# M5531 register map
File version: 1.0
Registers are 32-bit, read-write, reset 0x0 unless marked. A register's access mark holds for its fields unless they carry their own. Offsets are from the block's base; [hi:lo] are bit positions; {n}, {i} and the like mark numbered series; 'fields as' and 'values as' point back to an identical list.

## CRYPTO_NS (part 2 of 2) — CRYPTO Register Map
Base 0x5020A000
{0x358+4i} CRYPTO_HMAC_FDBCK{i} (i=0..87) — SHA/HMAC Output Feedback Data {i} After SHA/HMAC Operation
  [31:0] FDBCK — SHA/HMAC Feedback Information. The feedback value is 1728 bits in size for SHA1/2 and 2784 bits in size for SHA3. The SHA/HMAC engine uses the data from CRYPTO_HMAC_FDBCKx as the data inputted to CRYPTO_HMAC_FDBCKx for the next block in DMA cascade mode. The SHA/HMAC engine outputs feedback information for initial setting in the next block's operation. Software can store that feedback value temporarily. After switching back, fill the stored feedback value to CRYPTO_HMAC_FDBCKx in the same operation, and then continue the operation with the original setting.
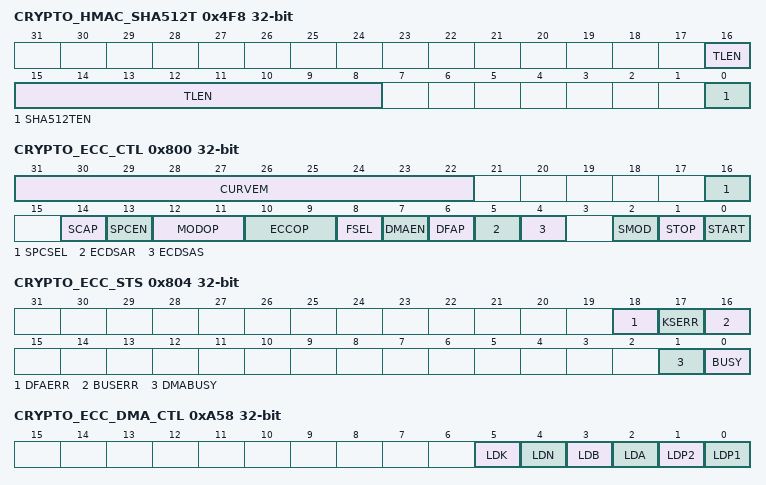
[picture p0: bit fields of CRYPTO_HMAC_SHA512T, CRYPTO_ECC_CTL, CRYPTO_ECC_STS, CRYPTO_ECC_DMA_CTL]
0x4F8 CRYPTO_HMAC_SHA512T — SHA/HMAC SHA512/t Control Register
  [16:8] TLEN — SHA512/t Output Digest Length. The TLEN is equal to value t of SHA512/t. It also means the output digest length of SHA512 /t. Note: TLEN 512, and TLEN is not 384
  [0] SHA512TEN — SHA512/t Engine Enable Bit
    0=Execute other function; 1=Execute SHA512/t function if SHA3EN=0, and SM3EN=0
0x4FC CRYPTO_HMAC_FBADDR — SHA/HMAC DMA Feedback Address Register
  [31:0] FBADDR — SHA/HMAC DMA Feedback Address. In DMA cascade mode, software can update DMA feedback address register for automatically reading and writing feedback values via DMA. The FBADDR keeps the feedback address of the feedback data for the next cascade operation. Based on the feedback address, the SHA/HMAC accelerator can read the feedback data of the last cascade operation from SRAM memory space and write the feedback data of the current cascade operation to SRAM memory space. The start of feedback address should be located at word boundary. In other words, bit 1 and 0 of FBADDR are ignored. FBADDR can be read and written. In DMA mode, software can update the next CRYPTO_HMAC_FBADDR before triggering START.
{0x500+4i} CRYPTO_HMAC_SHAKEDGST{i} ro (i=0..41) — SHA/HMAC SHAKE Digest Message {i}
  [31:0] DGST — SHA/HMAC SHAKE Digest Message Register. For SHAKE-128, the digest is stored in CRYPTO_HMAC_SHAKEDGST0 0 ~ CRYPTO_HMAC_ SHAKEDGST0 41. For SHAKE-256, the digest is stored in CRYPTO_HMAC_SHAKEDGST0 0 ~ CRYPTO_HMAC_ SHAKEDGST0 33.
0x800 CRYPTO_ECC_CTL — ECC Control Register
  [31:22] CURVEM — The key length of elliptic curve.
  [16] SPCSEL — Special Curve Selection
    0=Montgomery curve when SPCEN is 1; 1=Edwards curve when SPCEN is 1. SM2 curve when SPCEN is 0
  [14] SCAP — Side-channel Attack Protection
    0=Full speed without side-channel protection; 1=Less speed with side-channel protection
  [13] SPCEN — Special Curve Enable
    0=NIST suggested or SM2 curve; 1=Montgomery curve or Edwards curve
  [12:11] MODOP — Modulus Operation for PF. When SMOD is 0,
    0=Division:. Modulo:; 1=Multiplication:. Exponential:; 2=Addition:. Square root:; 3=Subtraction:
  [10:9] ECCOP — Point Operation for BF and PF. Besides above three input data, point operations still need the parameters of elliptic curve (CURVEA, CURVEB, CURVEN and CURVEM) as shown in Figure 6.27-11.
    0=Point multiplication:; 1=Modulus operation: choose by MODOP (CRYPTO_ECC_CTL[12:11]); 2=Point addition:; 3=Point doubling:
  [8] FSEL — Field Selection
    0=Binary Field (GF(2m )); 1=Prime Field (GF(p))
  [7] DMAEN — ECC Accelerator DMA Enable Bit. Only when START and DMAEN are 1, ECC DMA engine will be active.
    0=ECC DMA engine Disabled; 1=ECC DMA engine Enabled
  [6] DFAP — Differential Fault Attack Protection
    0=ECC engine differential fault attack protection Disabled; 1=ECC engine differential fault attack protection Enabled
  [5] ECDSAR — Generate R in ECDSA Signature Generation
    0=No effect; 1=Formula for generating R
  [4] ECDSAS — Generate S in ECDSA Signature Generation
    0=No effect; 1=Formula for generating S
  [2] SMOD — Special Modulus Operation in Prime Field
    0=Normal modulus operation; 1=Special modulus operation
  [1] STOP — ECC Accelerator Stop. This bit is always 0 when it is read back. Remember to clear ECC interrupt flag after stopping ECC accelerator.
    0=No effect; 1=Abort ECC accelerator and make it into idle state
  [0] START — ECC Accelerator Start. This bit is always 0 when it is read back. ECC accelerator will ignore this START signal when BUSY flag is 1.
    0=No effect; 1=Start ECC accelerator. BUSY flag will be set
0x804 CRYPTO_ECC_STS ro — ECC Status Register
  [18] DFAERR — ECC Engine Differential Fault Attack Error Flag
    0=No error; 1=Differential Fault Attack happened in ECC engine. The results from ECC engine are incorrect
  [17] KSERR — ECC Engine Access Key Store Error Flag
    0=No error; 1=Access error will stop ECC engine
  [16] BUSERR — ECC DMA Access Bus Error Flag
    0=No error; 1=Bus error will stop DMA operation and ECC accelerator
  [1] DMABUSY — ECC DMA Busy Flag
    0=ECC DMA is idle or finished; 1=ECC DMA is busy
  [0] BUSY — ECC Accelerator Busy Flag. Note: Remember to clear ECC interrupt flag after ECC accelerator is finished
    0=The ECC accelerator is idle or finished; 1=The ECC accelerator is under processing and protects all registers
{0x808+4i} CRYPTO_ECC_X1_{i:02} (i=0..17) — ECC the X-coordinate Word{i} of the First Point
  [31:0] POINTX1 — ECC the X-coordinate Value of the First Point. For B-163 or K-163, POINTX1 is stored in CRYPTO_ECC_X1_00~CRYPTO_ECC_X1_05. For B-233 or K-233, POINTX1 is stored in CRYPTO_ECC_X1_00~CRYPTO_ECC_X1_07. For B-283 or K-283, POINTX1 is stored in CRYPTO_ECC_X1_00~CRYPTO_ECC_X1_08. For B-409 or K-409, POINTX1 is stored in CRYPTO_ECC_X1_00~CRYPTO_ECC_X1_12. For B-571 or K-571, POINTX1 is stored in CRYPTO_ECC_X1_00~CRYPTO_ECC_X1_17. For P-192, POINTX1 is stored in CRYPTO_ECC_X1_00~CRYPTO_ECC_X1_05. For P-224, POINTX1 is stored in CRYPTO_ECC_X1_00~CRYPTO_ECC_X1_06. For P-256 or SM2, POINTX1 is stored in CRYPTO_ECC_X1_00~CRYPTO_ECC_X1_07. For P-384, POINTX1 is stored in CRYPTO_ECC_X1_00~CRYPTO_ECC_X1_11. For P-521, POINTX1 is stored in CRYPTO_ECC_X1_00~CRYPTO_ECC_X1_16
{0x850+4i} CRYPTO_ECC_Y1_{i:02} (i=0..17) — ECC the Y-coordinate Word{i} of the First Point
  [31:0] POINTY1 — ECC the Y-coordinate Value of the First Point. For B-163 or K-163, POINTY1 is stored in CRYPTO_ECC_Y1_00~CRYPTO_ECC_Y1_05. For B-233 or K-233, POINTY1 is stored in CRYPTO_ECC_Y1_00~CRYPTO_ECC_Y1_07. For B-283 or K-283, POINTY1 is stored in CRYPTO_ECC_Y1_00~CRYPTO_ECC_Y1_08. For B-409 or K-409, POINTY1 is stored in CRYPTO_ECC_Y1_00~CRYPTO_ECC_Y1_12. For B-571 or K-571, POINTY1 is stored in CRYPTO_ECC_Y1_00~CRYPTO_ECC_Y1_17. For P-192, POINTY1 is stored in CRYPTO_ECC_Y1_00~CRYPTO_ECC_Y1_05. For P-224, POINTY1 is stored in CRYPTO_ECC_Y1_00~CRYPTO_ECC_Y1_06. For P-256 or SM2, POINTY1 is stored in CRYPTO_ECC_Y1_00~CRYPTO_ECC_Y1_07. For P-384, POINTY1 is stored in CRYPTO_ECC_Y1_00~CRYPTO_ECC_Y1_11. For P-521, POINTY1 is stored in CRYPTO_ECC_Y1_00~CRYPTO_ECC_Y1_16
{0x898+4i} CRYPTO_ECC_X2_{i:02} (i=0..17) — ECC the X-coordinate Word{i} of the Second Point
  [31:0] POINTX2 — ECC the X-coordinate Value of the Second Point. For B-163 or K-163, POINTX2 is stored in CRYPTO_ECC_X2_00~CRYPTO_ECC_X2_05. For B-233 or K-233, POINTX2 is stored in CRYPTO_ECC_X2_00~CRYPTO_ECC_X2_07. For B-283 or K-283, POINTX2 is stored in CRYPTO_ECC_X2_00~CRYPTO_ECC_X2_08. For B-409 or K-409, POINTX2 is stored in CRYPTO_ECC_X2_00~CRYPTO_ECC_X2_12. For B-571 or K-571, POINTX2 is stored in CRYPTO_ECC_X2_00~CRYPTO_ECC_X2_17. For P-192, POINTX2 is stored in CRYPTO_ECC_X2_00~CRYPTO_ECC_X2_05. For P-224, POINTX2 is stored in CRYPTO_ECC_X2_00~CRYPTO_ECC_X2_06. For P-256 or SM2, POINTX2 is stored in CRYPTO_ECC_X2_00~CRYPTO_ECC_X2_07. For P-384, POINTX2 is stored in CRYPTO_ECC_X2_00~CRYPTO_ECC_X2_11. For P-521, POINTX2 is stored in CRYPTO_ECC_X2_00~CRYPTO_ECC_X2_16
{0x8E0+4i} CRYPTO_ECC_Y2_{i:02} (i=0..17) — ECC the Y-coordinate Word{i} of the Second Point
  [31:0] POINTY2 — ECC the Y-coordinate Value of the Second Point. For B-163 or K-163, POINTY2 is stored in CRYPTO_ECC_Y2_00~CRYPTO_ECC_Y2_05. For B-233 or K-233, POINTY2 is stored in CRYPTO_ECC_Y2_00~CRYPTO_ECC_Y2_07. For B-283 or K-283, POINTY2 is stored in CRYPTO_ECC_Y2_00~CRYPTO_ECC_Y2_08. For B-409 or K-409, POINTY2 is stored in CRYPTO_ECC_Y2_00~CRYPTO_ECC_Y2_12. For B-571 or K-571, POINTY2 is stored in CRYPTO_ECC_Y2_00~CRYPTO_ECC_Y2_17. For P-192, POINTY2 is stored in CRYPTO_ECC_Y2_00~CRYPTO_ECC_Y2_05. For P-224, POINTY2 is stored in CRYPTO_ECC_Y2_00~CRYPTO_ECC_Y2_06. For P-256 or SM2, POINTY2 is stored in CRYPTO_ECC_Y2_00~CRYPTO_ECC_Y2_07. For P-384, POINTY2 is stored in CRYPTO_ECC_Y2_00~CRYPTO_ECC_Y2_11. For P-521, POINTY2 is stored in CRYPTO_ECC_Y2_00~CRYPTO_ECC_Y2_16
{0x928+4i} CRYPTO_ECC_A_{i:02} (i=0..17) — ECC the Parameter CURVEA Word{i} of Elliptic Curve
  [31:0] CURVEA — ECC the Parameter CURVEA Value of Elliptic Curve. For B-163 or K-163, CURVEA is stored in CRYPTO_ECC_A_00~CRYPTO_ECC_A_05. For B-233 or K-233, CURVEA is stored in CRYPTO_ECC_A_00~CRYPTO_ECC_A_07. For B-283 or K-283, CURVEA is stored in CRYPTO_ECC_A_00~CRYPTO_ECC_A_08. For B-409 or K-409, CURVEA is stored in CRYPTO_ECC_A_00~CRYPTO_ECC_A_12. For B-571 or K-571, CURVEA is stored in CRYPTO_ECC_A_00~CRYPTO_ECC_A_17. For P-192, CURVEA is stored in CRYPTO_ECC_A_00~CRYPTO_ECC_A_05. For P-224, CURVEA is stored in CRYPTO_ECC_A_00~CRYPTO_ECC_A_06. For P-256 or SM2, CURVEA is stored in CRYPTO_ECC_A_00~CRYPTO_ECC_A_07. For P-384, CURVEA is stored in CRYPTO_ECC_A_00~CRYPTO_ECC_A_11. For P-521, CURVEA is stored in CRYPTO_ECC_A_00~CRYPTO_ECC_A_16
{0x970+4i} CRYPTO_ECC_B_{i:02} (i=0..17) — ECC the Parameter CURVEB Word{i} of Elliptic Curve
  [31:0] CURVEB — ECC the Parameter CURVEB Value of Elliptic Curve. For B-163 or K-163, CURVEB is stored in CRYPTO_ECC_B_00~CRYPTO_ECC_B_05. For B-233 or K-233, CURVEB is stored in CRYPTO_ECC_B_00~CRYPTO_ECC_B_07. For B-283 or K-283, CURVEB is stored in CRYPTO_ECC_B_00~CRYPTO_ECC_B_08. For B-409 or K-409, CURVEB is stored in CRYPTO_ECC_B_00~CRYPTO_ECC_B_12. For B-521 or K-521, CURVEB is stored in CRYPTO_ECC_B_00~CRYPTO_ECC_B_17. For P-192, CURVEB is stored in CRYPTO_ECC_B_00~CRYPTO_ECC_B_05. For P-224, CURVEB is stored in CRYPTO_ECC_B_00~CRYPTO_ECC_B_06. For P-256 or SM2, CURVEB is stored in CRYPTO_ECC_B_00~CRYPTO_ECC_B_07. For P-384, CURVEB is stored in CRYPTO_ECC_B_00~CRYPTO_ECC_B_11. For P-521, CURVEB is stored in CRYPTO_ECC_B_00~CRYPTO_ECC_B_16
{0x9B8+4i} CRYPTO_ECC_N_{i:02} (i=0..17) — ECC the Parameter CURVEN Word{i} of Elliptic Curve
  [31:0] CURVEN — ECC the Parameter CURVEN Value of Elliptic Curve. In GF(p), CURVEN is the prime p. In GF(2m), CURVEN is the irreducible polynomial. For B-163 or K-163, CURVEN is stored in CRYPTO_ECC_N_00~CRYPTO_ECC_N_05. For B-233 or K-233, CURVEN is stored in CRYPTO_ECC_N_00~CRYPTO_ECC_N_07. For B-283 or K-283, CURVEN is stored in CRYPTO_ECC_N_00~CRYPTO_ECC_N_08. For B-409 or K-409, CURVEN is stored in CRYPTO_ECC_N_00~CRYPTO_ECC_N_12. For B-571 or K-571, CURVEN is stored in CRYPTO_ECC_N_00~CRYPTO_ECC_N_17. For P-192, CURVEN is stored in CRYPTO_ECC_N_00~CRYPTO_ECC_N_05. For P-224, CURVEN is stored in CRYPTO_ECC_N_00~CRYPTO_ECC_N_06. For P-256 or SM2, CURVEN is stored in CRYPTO_ECC_N_00~CRYPTO_ECC_N_07. For P-384, CURVEN is stored in CRYPTO_ECC_N_00~CRYPTO_ECC_N_11. For P-521, CURVEN is stored in CRYPTO_ECC_N_00~CRYPTO_ECC_N_16
{0xA00+4i} CRYPTO_ECC_K_{i:02} wo (i=0..17) — ECC the Scalar SCALARK Word{i} of Point Multiplication
  [31:0] SCALARK — ECC the Scalar SCALARK Value of Point Multiplication. Because the SCALARK usually stores the private key, ECC accelerator do not allow to read the register SCALARK. For B-163 or K-163, SCALARK is stored in CRYPTO_ECC_K_00~CRYPTO_ECC_K_05. For B-233 or K-233, SCALARK is stored in CRYPTO_ECC_K_00~CRYPTO_ECC_K_07. For B-283 or K-283, SCALARK is stored in CRYPTO_ECC_K_00~CRYPTO_ECC_K_08. For B-409 or K-409, SCALARK is stored in CRYPTO_ECC_K_00~CRYPTO_ECC_K_12. For B-571 or K-571, SCALARK is stored in CRYPTO_ECC_K_00~CRYPTO_ECC_K_17. For P-192, SCALARK is stored in CRYPTO_ECC_K_00~CRYPTO_ECC_K_05. For P-224, SCALARK is stored in CRYPTO_ECC_K_00~CRYPTO_ECC_K_06. For P-256 or SM2, SCALARK is stored in CRYPTO_ECC_K_00~CRYPTO_ECC_K_07. For P-384, SCALARK is stored in CRYPTO_ECC_K_00~CRYPTO_ECC_K_11. For P-521, SCALARK is stored in CRYPTO_ECC_K_00~CRYPTO_ECC_K_16
0xA48 CRYPTO_ECC_SADDR — ECC DMA Source Address Register
0xA4C CRYPTO_ECC_DADDR — ECC DMA Destination Address Register
  [31:0] DADDR — ECC DMA Destination Address. The ECC accelerator supports DMA function to transfer the DATA and PARAMETER between SRAM memory and ECC accelerator. The DADDR keeps the destination address of the data buffer where output data of ECC engine will be stored. Based on the destination address, the ECC accelerator can write the result data back to SRAM memory space after the ECC operation is finished. The start of destination address should be located at word boundary. That is, bit 1 and 0 of DADDR are ignored. DADDR can be read and written. In DMA mode, software must update the CRYPTO_ECC_DADDR before triggering START.
0xA50 CRYPTO_ECC_STARTREG — ECC Starting Address of Updated Registers
  [31:0] STARTREG — ECC Starting Address of Updated Registers. The address of the updated registers that DMA feeds the first data or parameter to ECC engine. When ECC engine is active, ECC accelerator does not allow users to modify STARTRE.G. For example, to update input data from register CRYPTO_ECC POINTX1. Thus, the value of STARTREG is 0x808.
0xA54 CRYPTO_ECC_WORDCNT — ECC DMA Word Count
  [31:0] WORDCNT — ECC DMA Word Count. The CRYPTO_ECC_WORDCNT keeps the word count of source data that is for the required input data of ECC accelerator with various operations in DMA mode. Although CRYPTO_ECC_WORDCNT is 32-bit, the maximum of word count in ECC accelerator is 144 words. CRYPTO_ECC_WORDCNT can be read and written.
0xA58 CRYPTO_ECC_DMA_CTL — ECC DMA Control Register
  [5] LDK — The Control Signal of Register for SCALARK
    0=The register for SCALARK is not modified by DMA or user; 1=The register for SCALARK is modified by DMA or user
  [4] LDN — The Control Signal of Register for the Parameter CURVEN of Elliptic Curve
    0=The register for CURVEN is not modified by DMA or user; 1=The register for CURVEN is modified by DMA or user
  [3] LDB — The Control Signal of Register for the Parameter CURVEB of Elliptic Curve
    0=The register for CURVEB is not modified by DMA or user; 1=The register for CURVEB is modified by DMA or user
  [2] LDA — The Control Signal of Register for the Parameter CURVEA of Elliptic Curve
    0=The register for CURVEA is not modified by DMA or user; 1=The register for CURVEA is modified by DMA or user
  [1] LDP2 — The Control Signal of Register POINTX2 and POINTY2 for the x and Y Coordinate of the Second Point
    0=The register for POINTX2 and POINTY2 is not modified by DMA or user; 1=The register for POINTX2 and POINTY2 is modified by DMA or user
  [0] LDP1 — The Control Signal of Register POINTX1 and POINTY1 for the x and Y Coordinate of the First Point
    0=The register for POINTX1 and POINTY1 is not modified by DMA or user; 1=The register for POINTX1 and POINTY1 is modified by DMA or user
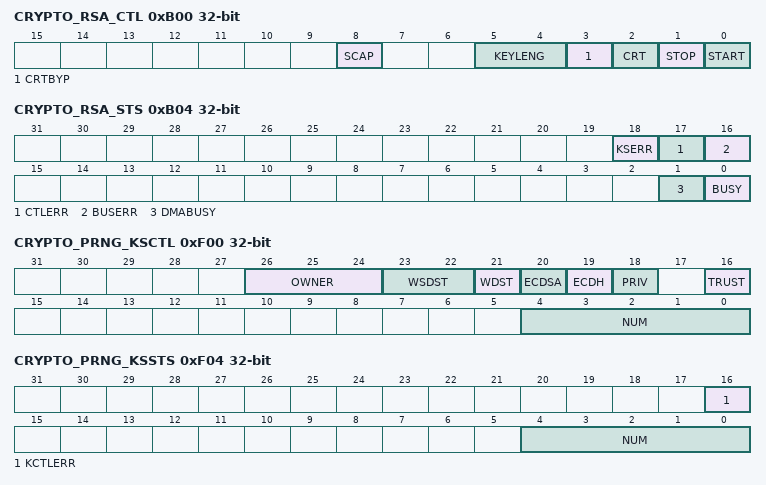
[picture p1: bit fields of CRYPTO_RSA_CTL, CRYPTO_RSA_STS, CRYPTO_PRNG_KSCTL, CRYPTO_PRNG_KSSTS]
0xB00 CRYPTO_RSA_CTL — RSA Control Register
  [8] SCAP — Side Channel Attack Protection Enable Control
    0=Side Channel Attack Protection Disabled; 1=Side Channel Attack Protection Enabled
  [5:4] KEYLENG — The Key Length of RSA Operation
    0=1024-bits; 1=2048-bits; 2=3072-bits; 3=4096-bits
  [3] CRTBYP — CRT Bypass Enable Control. CRT bypass is only used in CRT decryption with the same key. CRT mode saved the data when the first time CRT decryption (CRTBYP is 0), then users can use these already known data to bypass some operation when the second time to the latest time CRT decryption (CRTBYP is 1) for improve performance. Note: Users cannot set CRTBYP to 1 in non-CRT mode (CRT (CRYPTO_RSA_CTL[2]) is 0).
    0=CRT Bypass Disabled; 1=CRT Bypass Enabled
  [2] CRT — CRT Enable Control. CRT is only used in decryption with key length 2048, 3072,4096 bits.
    0=CRT Disabled; 1=CRT Enabled
  [1] STOP — RSA Accelerator Stop. This bit is always 0 when it is read back. Remember to clear RSA interrupt flag after stopping RSA accelerator.
    0=No effect; 1=Abort RSA accelerator and make it into initial state
  [0] START — RSA Accelerator Start. This bit is always 0 when it is read back. RSA accelerator will ignore this START signal when BUSY flag is 1.
    0=No effect; 1=Start RSA accelerator. BUSY flag will be set
0xB04 CRYPTO_RSA_STS ro — RSA Status Register
  [18] KSERR — RSA Engine Access Key Store Error Flag
    0=No error; 1=Access error will stop RSA engine
  [17] CTLERR — RSA Control Register Error Flag. Note: If users use the error combination of control, even though they don't set START(CRYPTO_RSA_CTL[0]) to 1, CTLERR still be set to 1.
    0=No error; 1=RSA control error. RSA will not start in the unsupported situation
  [16] BUSERR — RSA DMA Access Bus Error Flag
    0=No error; 1=Bus error will stop DMA operation and RSA accelerator
  [1] DMABUSY — RSA DMA Busy Flag
    0=RSA DMA is idle or finished; 1=RSA DMA is busy
  [0] BUSY — RSA Accelerator Busy Flag. Remember to clear RSA interrupt flag after RSA accelerator finished.
    0=The RSA accelerator is idle or finished; 1=The RSA accelerator is under processing and protects all registers
0xB08 CRYPTO_RSA_SADDR0 — RSA DMA Source Address Register0
  [31:0] SADDR0 — RSA DMA Source Address Register0. The RSA accelerator supports DMA function to transfer the DATA and PARAMETER between SRAM memory space and RSA accelerator. This register is stored the address of RSA the Base of Exponentiation (M).
0xB0C CRYPTO_RSA_SADDR1 — RSA DMA Source Address Register1
  [31:0] SADDR1 — RSA DMA Source Address Register1. The RSA accelerator supports DMA function to transfer the DATA and PARAMETER between SRAM memory space and RSA accelerator. This register is stored the address of RSA the Base of Modulus Operation (N).
0xB10 CRYPTO_RSA_SADDR2 — RSA DMA Source Address Register2
  [31:0] SADDR2 — RSA DMA Source Address Register2. The RSA accelerator supports DMA function to transfer the DATA and PARAMETER between SRAM memory space and RSA accelerator. This register is stored the address of RSA the Exponent of Exponentiation (E).
0xB14 CRYPTO_RSA_SADDR3 — RSA DMA Source Address Register3
  [31:0] SADDR3 — RSA DMA Source Address Register3. The RSA accelerator supports DMA function to transfer the DATA and PARAMETER between SRAM memory space and RSA accelerator. This register is stored the address of RSA the Factor of Modulus Operation (p).
0xB18 CRYPTO_RSA_SADDR4 — RSA DMA Source Address Register4
  [31:0] SADDR4 — RSA DMA Source Address Register4. The RSA accelerator supports DMA function to transfer the DATA and PARAMETER between SRAM memory space and RSA accelerator. This register is stored the address of RSA the Factor of Modulus Operation (q).
0xB1C CRYPTO_RSA_DADDR — RSA DMA Destination Address Register
  [31:0] DADDR — RSA DMA Destination Address Register. The RSA accelerator supports DMA function to transfer the DATA and PARAMETER between SRAM memory space and RSA accelerator. This register is stored the address of RSA DMA Destination Address Register (Ans).
{0xB20+4i} CRYPTO_RSA_MADDR{i} (i=0..6) — RSA DMA Middle Address Register{i}
  [31:0] MADDR{i} — RSA DMA Middle Address Register{i}. The RSA accelerator supports DMA function to transfer the DATA and PARAMETER between SRAM memory space and RSA accelerator.
0xF00 CRYPTO_PRNG_KSCTL wo — PRNG Key Control Register
  [26:24] OWNER — Write Key Owner Selection Bits
    0=Only for AES use; 1=Only for HMAC engine (excludes HMAC-SHA3 series) use; 4=Only for ECC engine use; 5=Only for CPU engine use
  [23:22] WSDST — Write Key Store Destination
    0=Key is written to the SRAM of Key Store; 1=Key is written to the FLASH of Key Store; 2=Key is written to the OTP of Key Store
  [21] WDST — Write Key Destination
    0=Key is written to registers CRYPTO_PRNG_KEYx; 1=Key is written to Key Store
  [20] ECDSA — ECDSA Control Bit. Note: When ECDSA was set to '1', 1. PRNG seed must be from TRNG and key must be written to the SRAM of Key Store (WSDST, CRYPTO_PRNG_KSCTL[23:22] must set to '00'). Otherwise, KCTLERR will become '1'(CRYPTO_PRNG_KSSTS[16]). 2. Key must in the interval [1, n-1] (the parameter n is from ECC). The value of n cannot be 0 or 1, otherwise, PRNG will always keep busy.
    1=Key is written to Key Store and used in ECDSA
  [19] ECDH — ECDH Control Bit. Note: When ECDH was set to '1', 1. PRNG seed must be from TRNG and key must be written to the SRAM of Key Store (WSDST, CRYPTO_PRNG_KSCTL[23:22] must set to '00'). Otherwise, KCTLERR will become '1'(CRYPTO_PRNG_KSSTS[16]).2. Key must in the interval [1, n-1] (the parameter n is from ECC). The value of n cannot be 0 or 1, otherwise, PRNG will always keep busy.
    1=key is written to Key Store and used in ECDH
  [18] PRIV — Write Key Privilege Selection Bit
    0=Set written key as the non-privilege key; 1=Set written key as the privilege key
  [16] TRUST — Write Key Trust Selection Bit
    0=Set written key as the non-secure key; 1=Set written key as the secure key
  [4:0] NUM — Write Key Number. The key number is sent to Key Store. Note: Only for destination Is OTP of Key Store.
0xF04 CRYPTO_PRNG_KSSTS ro — PRNG Key Status Register
  [16] KCTLERR — PRNG Key Control Register Error Flag
    0=No error; 1=PRNG key control error. When PRNG execute ECDSA or ECDH, but PRNG seed not from TRNG or key is not written to the SRAM of Key Store (WSDST, CRYPTO_PRNG_KSCTL[23:22] is not equal to '00')
  [4:0] NUM — Key Number. The key number is generated by Key Store
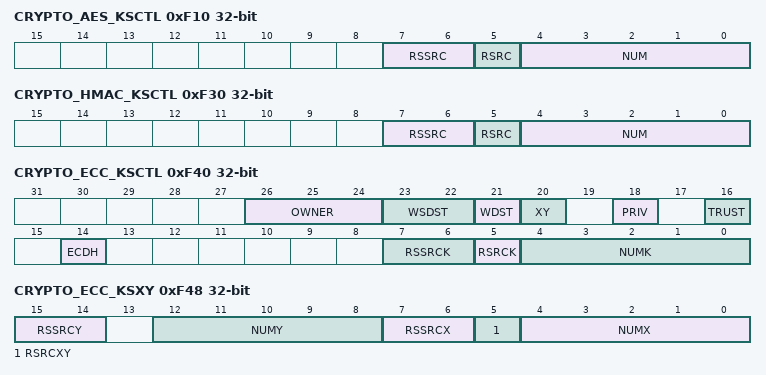
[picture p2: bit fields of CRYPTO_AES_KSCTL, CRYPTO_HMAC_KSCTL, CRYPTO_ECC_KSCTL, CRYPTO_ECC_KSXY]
0xF10 CRYPTO_AES_KSCTL wo — AES Key Control Register
  [7:6] RSSRC — Read Key Store Source. RSSRC takes effect only when RSRC is 1 (the key is from Key Store).
    0=Key is read from the SRAM of Key Store; 1=Key is read from the FLASH of Key Store; 2=Key is read from the OTP of Key Store
  [5] RSRC — Read Key Source
    0=Key is read from registers CRYPTO_AESx_KEYx; 1=Key is read from Key Store
  [4:0] NUM — Read Key Number. The key number is sent to Key Store
0xF30 CRYPTO_HMAC_KSCTL wo — HMAC Key Control Register
  [7:6] RSSRC — Read Key Store Source. RSSRC takes effect only when RSRC is 1 (the key is from Key Store).
    0=Key is read from the SRAM of Key Store; 1=Key is read from the FLASH of Key Store
  [5] RSRC — Read Key Source
    0=Key is read from HMAC registers; 1=Key is read from Key Store
  [4:0] NUM — Read Key Number. The key number is sent to Key Store
0xF40 CRYPTO_ECC_KSCTL wo — ECC Key Control Register
  [26:24] OWNER — Write Key Owner Selection Bits
    0=The ECDH written key is only for AES used; 1=The ECDH written key is only for HMAC engine used; 4=The ECDH written key is only for ECC engine used; 5=The ECDH written key is only for CPU engine use
  [23:22] WSDST — Write Key Store Destination. WSDST takes effect only when WDST is 1 (the key is written to Key Store).
    0=The ECDH written key is written to the SRAM of Key Store; 1=The ECDH written key is written to the FLASH of Key Store; 2=The ECDH written key is written to the OTP of Key Store
  [21] WDST — Write Key Destination
    0=The ECDH written key is in registers CRYPTO_ECC_X1 and CRYPTO_ECC_Y; 1=The ECDH written key is written to Key Store
  [20] XY — ECDH Output Select Bit
    0=The ECDH written key is from X-coordinate Value; 1=The ECDH written key is from Y-coordinate Value
  [18] PRIV — Write Key Privilege Selection Bit
    0=Set ECDH written key as the non-privilege key; 1=Set ECDH written key as the privilege key
  [16] TRUST — Write Key Trust Selection Bit
    0=Set ECDH written key as the non-secure key; 1=Set ECDH written key as the secure key
  [14] ECDH — ECDH Control Bit
    1=Set ECC operation is in ECDH. When this bit and RSRCK are equal to 0x1, ECC will read ECDH private key to CRYPTO_ECC_K from Key Store
  [7:6] RSSRCK — Read Key Store Source for Key Number K. RSSRCK takes effect only when RSRCK is 1 (the key is from Key Store).
    values as CRYPTO_AES_KSCTL.RSSRC
  [5] RSRCK — Read Key Source for Key Number K
    0=Key is read from ECC registers; 1=Key is read from Key Store
  [4:0] NUMK — Read Key Number K
0xF44 CRYPTO_ECC_KSSTS ro — ECC Key Status Register
  [4:0] NUM — Key Number. The key number is generated by Key Store after ECDH.
0xF48 CRYPTO_ECC_KSXY wo — ECC XY Number Register
  [15:14] RSSRCY — Read Key Store Source for Key Number Y. RSSRCY takes effect only when RSRCXY is 1 (the key is from Key Store).
    values as CRYPTO_AES_KSCTL.RSSRC
  [12:8] NUMY — Read Key Number Y
  [7:6] RSSRCX — Read Key Store Source for Key Number X. RSSRCX takes effect only when RSRCXY is 1 (the key is from Key Store).
    values as CRYPTO_AES_KSCTL.RSSRC
  [5] RSRCXY — Read Key Source for Key Number X and Y
    values as CRYPTO_ECC_KSCTL.RSRCK
  [4:0] NUMX — Read Key Number X
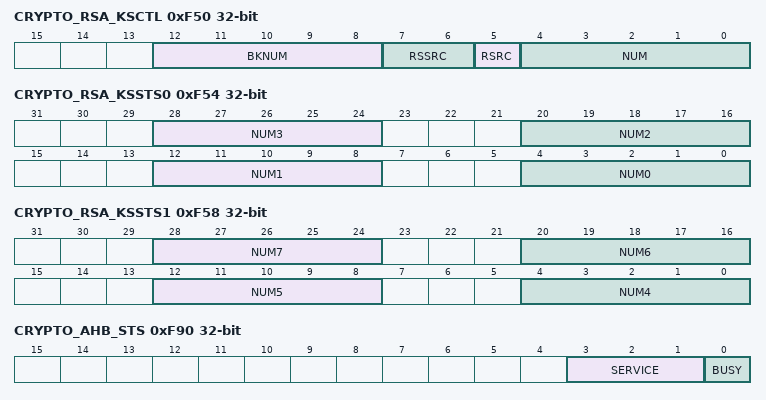
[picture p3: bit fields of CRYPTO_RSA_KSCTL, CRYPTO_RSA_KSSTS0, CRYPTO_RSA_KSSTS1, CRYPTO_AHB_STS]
0xF50 CRYPTO_RSA_KSCTL wo — RSA Key Control Register
  [12:8] BKNUM — Read Exponent Blind Key Number. The key number is sent to Key Store, and its destination always be the SRAM of Key Store. CPU cannot read the exponent blind key. Note: Use this key number, only when executing SCAP but no-CRT mode. When allocate space of Key Store, key owner selection bits (KS_METADATA[18:16]) should be '010'.
  [7:6] RSSRC — Read Key Store Source. RSSRC takes effect only when RSRC is 1 (the key is from Key Store).
    values as CRYPTO_HMAC_KSCTL.RSSRC
  [5] RSRC — Read Key Source
    0=Key is read from RSA engine; 1=Key is read from Key Store
  [4:0] NUM — Read Key Number. The key number is sent to Key Store
0xF54 CRYPTO_RSA_KSSTS0 — RSA Key Status Register 0
  [28:24] NUM3 — Key Number3. The key number is generated by Key Store, RSA can get or store the intermediate temporary value by key number in the Key Store while operating. Note: The size of this key as key length.
  [20:16] NUM2 — Key Number2. The key number is generated by Key Store, RSA can get or store the intermediate temporary value by key number in the Key Store while operating. Note: The size of this key as key length.
  [12:8] NUM1 — Key Number1. The key number is generated by Key Store, RSA can get complete q by key number in Key Store while operating. Note: The size of this key as half key length.
  [4:0] NUM0 — Key Number0. The key number is generated by Key Store, RSA can get complete p by key number in Key Store while operating. Note: The size of this key as half key length.
0xF58 CRYPTO_RSA_KSSTS1 — RSA Key Status Register 1
  [28:24] NUM7 — Key Number7. The key number is generated by Key Store, RSA can get or store the intermediate temporary value by key number in Key Store while operating. Note: The size of this key as key length.
  [20:16] NUM6 — Key Number6. The key number is generated by Key Store, RSA can get or store the intermediate temporary value by key number in Key Store while operating. Note: The size of this key as key length.
  [12:8] NUM5 — Key Number5. The key number is generated by Key Store, RSA can get or store the intermediate temporary value by key number in Key Store while operating. Note: The size of this key as half key length.
  [4:0] NUM4 — Key Number4. The key number is generated by Key Store, RSA can get or store the intermediate temporary value by key number in Key Store while operating. Note: The size of this key as half key length.
0xF90 CRYPTO_AHB_STS ro — CRYPTO AHB Master Status Register
  [3:1] SERVICE — AHB Master Service
    1=AHB master is servicing AES engine when BUSY is 1; 2=AHB master is servicing SHA/HMAC engine when BUSY is 1; 4=AHB master is servicing ECC engine when BUSY is 1; 5=AHB master is servicing RSA engine when BUSY is 1
  [0] BUSY — AHB Master Busy
    0=AHB Master is idle or finished; 1=AHB Master is busy
